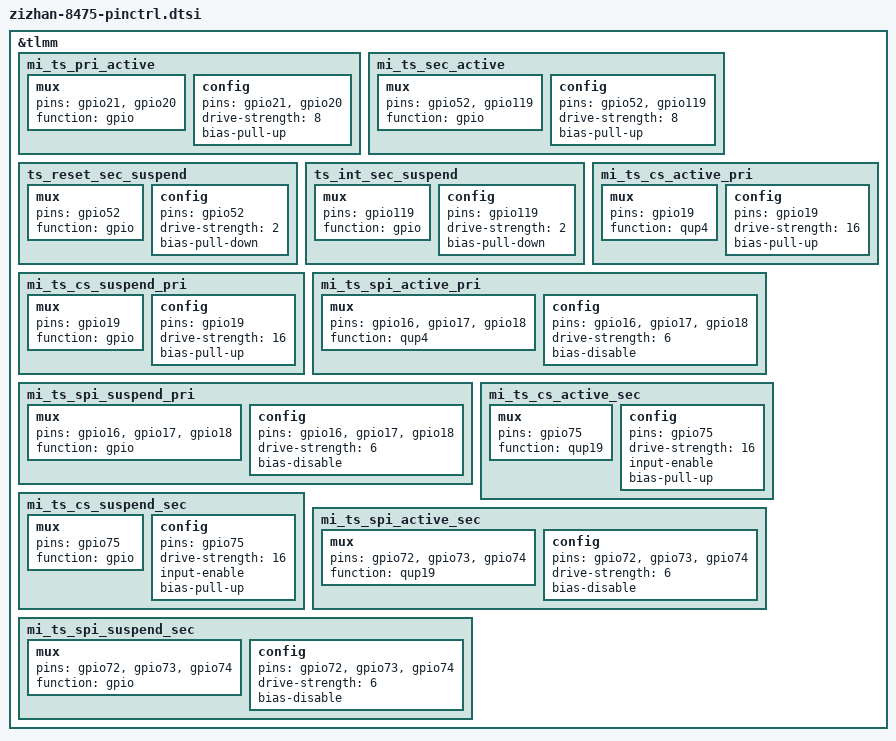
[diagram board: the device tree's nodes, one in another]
/*for zizhan pinctrl */

&tlmm {
	mi_ts_pri_active: mi_ts_pri_active {
		mux {
				pins = "gpio21", "gpio20";
				function = "gpio";
		};

		config {
				pins = "gpio21", "gpio20";
				drive-strength = <8>;
				bias-pull-up;
		};
	};
	mi_ts_sec_active: mi_ts_sec_active {
		mux {
				pins = "gpio52", "gpio119";
				function = "gpio";
		};

		config {
				pins = "gpio52", "gpio119";
				drive-strength = <8>;
				bias-pull-up;
		};
	};

	ts_reset_sec_suspend: ts_reset_sec_suspend {
		mux {
			pins = "gpio52";
			function = "gpio";
		};

		config {
			pins = "gpio52";
			drive-strength = <2>;
			bias-pull-down;
		};
	};

	ts_int_sec_suspend: ts_int_sec_suspend {
		mux {
			pins = "gpio119";
			function = "gpio";
		};

		config {
			pins = "gpio119";
			drive-strength = <2>;
			bias-pull-down;
		};
	};

	mi_ts_cs_active_pri: mi_ts_cs_active_pri {
		mux {
			pins = "gpio19";
			function = "qup4";
		};

		config {
			pins = "gpio19";
			drive-strength = <16>;
			bias-pull-up;
		};
	};

	mi_ts_cs_suspend_pri: mi_ts_cs_suspend_pri {
		mux {
			pins = "gpio19";
			function = "gpio";
		};

		config {
			pins = "gpio19";
			drive-strength = <16>;
			bias-pull-up;
		};
	};

	mi_ts_spi_active_pri: mi_ts_spi_active_pri {
			mux {
				pins = "gpio16", "gpio17", "gpio18";
				function = "qup4";
			};

			config {
				pins = "gpio16", "gpio17", "gpio18";
				drive-strength = <6>;
				bias-disable;
			};
		};

	mi_ts_spi_suspend_pri: mi_ts_spi_suspend_pri {
		mux {
			pins = "gpio16", "gpio17", "gpio18";
			function = "gpio";
		};

		config {
			pins = "gpio16", "gpio17", "gpio18";
			drive-strength = <6>;
			bias-disable;
		};
	};

	mi_ts_cs_active_sec: mi_ts_cs_active_sec {
		mux {
			pins = "gpio75";
			function = "qup19";
		};

		config {
			pins = "gpio75";
			drive-strength = <16>;
			input-enable;
			bias-pull-up;
		};
	};

	mi_ts_cs_suspend_sec: mi_ts_cs_suspend_sec {
		mux {
			pins = "gpio75";
			function = "gpio";
		};

		config {
			pins = "gpio75";
			drive-strength = <16>;
			input-enable;
			bias-pull-up;
		};
	};

	mi_ts_spi_active_sec: mi_ts_spi_active_sec {
			mux {
				pins = "gpio72", "gpio73", "gpio74";
				function = "qup19";
			};

			config {
				pins = "gpio72", "gpio73", "gpio74";
				drive-strength = <6>;
				bias-disable;
			};
		};

	mi_ts_spi_suspend_sec: mi_ts_spi_suspend_sec {
		mux {
			pins = "gpio72", "gpio73", "gpio74";
			function = "gpio";
		};

		config {
			pins = "gpio72", "gpio73", "gpio74";
			drive-strength = <6>;
			bias-disable;
		};
	};
};
